VERSION ""

NS_ :

BS_:

BU_: HVC

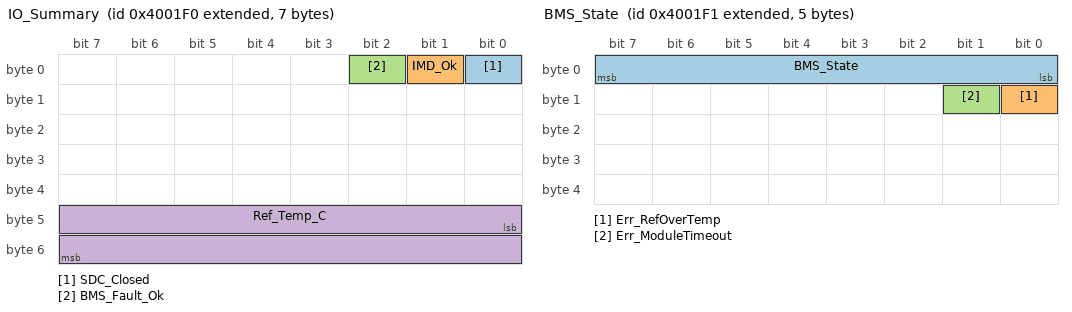
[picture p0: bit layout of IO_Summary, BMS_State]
BO_ 2151678448 IO_Summary: 7 HVC
 SG_ SDC_Closed : 0|1@1+ (1,0) [0|1] "" Vector__XXX
 SG_ IMD_Ok : 1|1@1+ (1,0) [0|1] "" Vector__XXX
 SG_ BMS_Fault_Ok : 2|1@1+ (1,0) [0|1] "" Vector__XXX
 SG_ Ref_Temp_C : 40|16@1- (0.01,0) [-327.68|327.67] "degC" Vector__XXX

BO_ 2151678451 IO_Current: 8 HVC
 SG_ Current_Low_mA : 0|32@1- (1,0) [-2147483648|2147483647] "mA" Vector__XXX
 SG_ Current_High_mA : 32|32@1- (1,0) [-2147483648|2147483647] "mA" Vector__XXX

BO_ 2151678449 BMS_State: 5 HVC
 SG_ BMS_State : 0|8@1+ (1,0) [0|255] "" Vector__XXX
 SG_ Err_RefOverTemp : 8|1@1+ (1,0) [0|1] "" Vector__XXX
 SG_ Err_ModuleTimeout : 9|1@1+ (1,0) [0|1] "" Vector__XXX

BO_ 2151678452 SOC_Delta: 8 HVC
 SG_ SOC_Delta_Ams : 0|64@1- (1,0) [-9223372036854775808|9223372036854775807] "A*ms" Vector__XXX

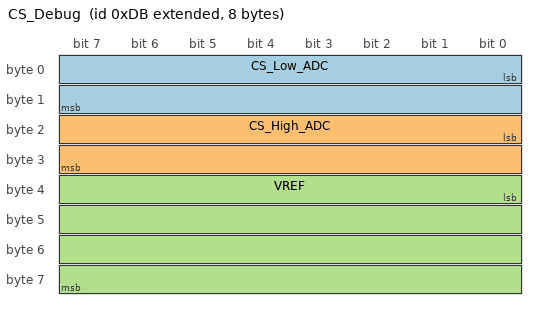
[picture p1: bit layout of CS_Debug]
BO_ 2147483867 CS_Debug: 8 HVC
 SG_ CS_Low_ADC : 0|16@1+ (1,0) [0|65535] "" Vector__XXX
 SG_ CS_High_ADC : 16|16@1+ (1,0) [0|65535] "" Vector__XXX
 SG_ VREF : 32|32@1+ (1,0) [0|4294967295] "mV" Vector__XXX

VAL_ 2151678449 BMS_State 0 "PRE_INIT" 1 "OK" 2 "ERRORED" ;
VAL_ 2151678449 Err_RefOverTemp 0 "Inactive" 1 "Active" ;
VAL_ 2151678449 Err_ModuleTimeout 0 "Inactive" 1 "Active" ;
